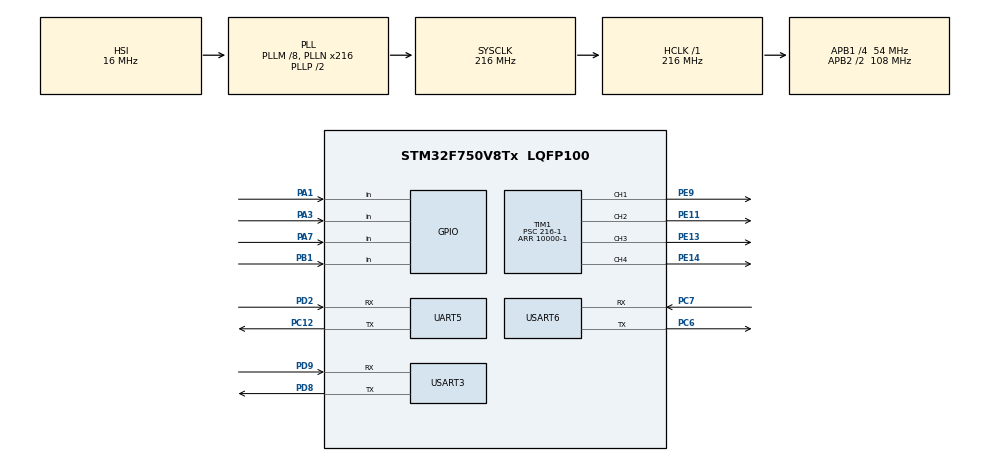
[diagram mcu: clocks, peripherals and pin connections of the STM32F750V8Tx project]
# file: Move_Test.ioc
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Mcu.Family=STM32F7
Mcu.Name=STM32F750V8Tx
Mcu.Package=LQFP100
NVIC.PriorityGroup=NVIC_PRIORITYGROUP_4
PA1.GPIO_PuPd=GPIO_PULLDOWN
PA1.Signal=GPIO_Input
PA3.GPIO_PuPd=GPIO_PULLDOWN
PA3.Signal=GPIO_Input
PA5.Signal=S_TIM2_CH1_ETR
PA7.GPIO_PuPd=GPIO_PULLDOWN
PA7.Signal=GPIO_Input
PB1.GPIO_PuPd=GPIO_PULLDOWN
PB1.Signal=GPIO_Input
PB10.Signal=S_TIM2_CH3
PB11.Signal=S_TIM2_CH4
PB3.Signal=S_TIM2_CH2
PC12.Mode=Asynchronous
PC12.Signal=UART5_TX
PC6.Mode=Asynchronous
PC6.Signal=USART6_TX
PC7.Mode=Asynchronous
PC7.Signal=USART6_RX
PD2.Mode=Asynchronous
PD2.Signal=UART5_RX
PD8.Mode=Asynchronous
PD8.Signal=USART3_TX
PD9.Mode=Asynchronous
PD9.Signal=USART3_RX
PE11.Signal=S_TIM1_CH2
PE13.Signal=S_TIM1_CH3
PE14.Signal=S_TIM1_CH4
PE9.Signal=S_TIM1_CH1
PH0/OSC_IN.Mode=HSE-External-Oscillator
PH0/OSC_IN.Signal=RCC_OSC_IN
PH1/OSC_OUT.Mode=HSE-External-Oscillator
PH1/OSC_OUT.Signal=RCC_OSC_OUT
ProjectManager.HeapSize=0x200
ProjectManager.StackSize=0x400
ProjectManager.TargetToolchain=MDK-ARM V5.32
RCC.AHBFreq_Value=216000000
RCC.APB1CLKDivider=RCC_HCLK_DIV4
RCC.APB1Freq_Value=54000000
RCC.APB1TimFreq_Value=108000000
RCC.APB2CLKDivider=RCC_HCLK_DIV2
RCC.APB2Freq_Value=108000000
RCC.APB2TimFreq_Value=216000000
RCC.CortexFreq_Value=216000000
RCC.HCLKFreq_Value=216000000
RCC.HSE_VALUE=25000000
RCC.HSI_VALUE=16000000
RCC.LSE_VALUE=32768
RCC.PLLM=8
RCC.PLLN=216
RCC.SYSCLKFreq_VALUE=216000000
RCC.SYSCLKSource=RCC_SYSCLKSOURCE_PLLCLK
RCC.USBFreq_Value=216000000
RCC.VCOOutputFreq_Value=432000000
SH.S_TIM1_CH1.0=TIM1_CH1,PWM Generation1 CH1
SH.S_TIM1_CH2.0=TIM1_CH2,PWM Generation2 CH2
SH.S_TIM1_CH3.0=TIM1_CH3,PWM Generation3 CH3
SH.S_TIM1_CH4.0=TIM1_CH4,PWM Generation4 CH4
SH.S_TIM2_CH1_ETR.0=TIM2_CH1
SH.S_TIM2_CH2.0=TIM2_CH2
SH.S_TIM2_CH3.0=TIM2_CH3
SH.S_TIM2_CH4.0=TIM2_CH4
TIM1.Channel-PWM\ Generation1\ CH1=TIM_CHANNEL_1
TIM1.Channel-PWM\ Generation2\ CH2=TIM_CHANNEL_2
TIM1.Channel-PWM\ Generation3\ CH3=TIM_CHANNEL_3
TIM1.Channel-PWM\ Generation4\ CH4=TIM_CHANNEL_4
TIM1.Period=10000-1
TIM1.Prescaler=216-1
USART3.VirtualMode-Asynchronous=VM_ASYNC
USART6.VirtualMode=VM_ASYNC
board=custom

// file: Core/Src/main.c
/* USER CODE BEGIN Header */
/**
  ******************************************************************************
  * @file           : main.c
  * @brief          : Main program body
  ******************************************************************************
  * @attention
  *
  * Copyright (c) 2023 STMicroelectronics.
  * All rights reserved.
  *
  * This software is licensed under terms that can be found in the LICENSE file
  * in the root directory of this software component.
  * If no LICENSE file comes with this software, it is provided AS-IS.
  *
  ******************************************************************************
  */
/* USER CODE END Header */
#include "main.h"
#include "tim.h"
#include "usart.h"
#include "gpio.h"

void SystemClock_Config(void);

int main(void)
{

  /* MCU Configuration--------------------------------------------------------*/

  /* Reset of all peripherals, Initializes the Flash interface and the Systick. */
  HAL_Init();

  /* Configure the system clock */
  SystemClock_Config();

  /* Initialize all configured peripherals */
  MX_GPIO_Init();
  MX_TIM1_Init();
  MX_USART3_UART_Init();
  MX_UART5_Init();
  MX_USART6_UART_Init();
  /* USER CODE BEGIN 2 */
  HAL_TIM_PWM_Start (&htim1,TIM_CHANNEL_2);
  __HAL_TIM_SET_COMPARE(&htim1, TIM_CHANNEL_2,5000);
  __HAL_TIM_SET_COMPARE(&htim1, TIM_CHANNEL_1,0);
  /* USER CODE END 2 */

  /* Infinite loop */
  while (1)
  {

  }
}

void SystemClock_Config(void)
{
  RCC_OscInitTypeDef RCC_OscInitStruct = {0};
  RCC_ClkInitTypeDef RCC_ClkInitStruct = {0};

  /** Configure the main internal regulator output voltage
  */
  __HAL_RCC_PWR_CLK_ENABLE();
  __HAL_PWR_VOLTAGESCALING_CONFIG(PWR_REGULATOR_VOLTAGE_SCALE1);

  /** Initializes the RCC Oscillators according to the specified parameters
  * in the RCC_OscInitTypeDef structure.
  */
  RCC_OscInitStruct.OscillatorType = RCC_OSCILLATORTYPE_HSI;
  RCC_OscInitStruct.HSIState = RCC_HSI_ON;
  RCC_OscInitStruct.HSICalibrationValue = RCC_HSICALIBRATION_DEFAULT;
  RCC_OscInitStruct.PLL.PLLState = RCC_PLL_ON;
  RCC_OscInitStruct.PLL.PLLSource = RCC_PLLSOURCE_HSI;
  RCC_OscInitStruct.PLL.PLLM = 8;
  RCC_OscInitStruct.PLL.PLLN = 216;
  RCC_OscInitStruct.PLL.PLLP = RCC_PLLP_DIV2;
  RCC_OscInitStruct.PLL.PLLQ = 2;
  if (HAL_RCC_OscConfig(&RCC_OscInitStruct) != HAL_OK)
  {
    Error_Handler();
  }

  /** Activate the Over-Drive mode
  */
  if (HAL_PWREx_EnableOverDrive() != HAL_OK)
  {
    Error_Handler();
  }

  /** Initializes the CPU, AHB and APB buses clocks
  */
  RCC_ClkInitStruct.ClockType = RCC_CLOCKTYPE_HCLK|RCC_CLOCKTYPE_SYSCLK
                              |RCC_CLOCKTYPE_PCLK1|RCC_CLOCKTYPE_PCLK2;
  RCC_ClkInitStruct.SYSCLKSource = RCC_SYSCLKSOURCE_PLLCLK;
  RCC_ClkInitStruct.AHBCLKDivider = RCC_SYSCLK_DIV1;
  RCC_ClkInitStruct.APB1CLKDivider = RCC_HCLK_DIV4;
  RCC_ClkInitStruct.APB2CLKDivider = RCC_HCLK_DIV2;

  if (HAL_RCC_ClockConfig(&RCC_ClkInitStruct, FLASH_LATENCY_7) != HAL_OK)
  {
    Error_Handler();
  }
}

/* USER CODE BEGIN 4 */

//void HAL_TIM_IC_CaptureCallback(TIM_HandleTypeDef *htim)
//{
//	if(htim->Instance == TIM6)
//	{
//		chassis_synthetic_control();
//	}
//}

/* USER CODE END 4 */

void Error_Handler(void)
{
  __disable_irq();
  while (1)
  {
  }
}
